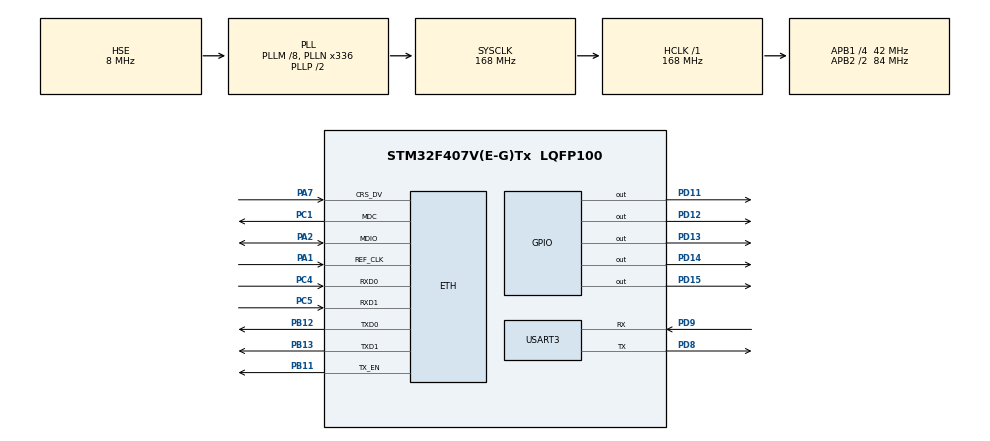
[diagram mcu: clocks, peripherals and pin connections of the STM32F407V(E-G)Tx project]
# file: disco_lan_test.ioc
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ETH.MACAddr=00\:80\:E1\:CB\:BB\:FF
ETH.MediaInterface=ETH_MEDIA_INTERFACE_RMII
LWIP.GATEWAY_ADDRESS=169.254.193.090
LWIP.IP_ADDRESS=169.254.193.140
LWIP.LWIP_DHCP=0
LWIP.LWIP_HTTPD=1
LWIP.NETMASK_ADDRESS=255.255.000.000
LWIP.Version=v2.0.3_Cube
Mcu.Family=STM32F4
Mcu.Name=STM32F407V(E-G)Tx
Mcu.Package=LQFP100
NVIC.PriorityGroup=NVIC_PRIORITYGROUP_0
PA1.Mode=RMII
PA1.Signal=ETH_REF_CLK
PA2.Mode=RMII
PA2.Signal=ETH_MDIO
PA7.Mode=RMII
PA7.Signal=ETH_CRS_DV
PB11.Mode=RMII
PB11.Signal=ETH_TX_EN
PB12.Mode=RMII
PB12.Signal=ETH_TXD0
PB13.Mode=RMII
PB13.Signal=ETH_TXD1
PC1.Mode=RMII
PC1.Signal=ETH_MDC
PC14-OSC32_IN.Mode=LSE-External-Oscillator
PC14-OSC32_IN.Signal=RCC_OSC32_IN
PC15-OSC32_OUT.Mode=LSE-External-Oscillator
PC15-OSC32_OUT.Signal=RCC_OSC32_OUT
PC4.Mode=RMII
PC4.Signal=ETH_RXD0
PC5.Mode=RMII
PC5.Signal=ETH_RXD1
PD11.Signal=GPIO_Output
PD12.Signal=GPIO_Output
PD13.Signal=GPIO_Output
PD14.Signal=GPIO_Output
PD15.Signal=GPIO_Output
PD8.Mode=Asynchronous
PD8.Signal=USART3_TX
PD9.Mode=Asynchronous
PD9.Signal=USART3_RX
PH0-OSC_IN.Mode=HSE-External-Oscillator
PH0-OSC_IN.Signal=RCC_OSC_IN
PH1-OSC_OUT.Mode=HSE-External-Oscillator
PH1-OSC_OUT.Signal=RCC_OSC_OUT
ProjectManager.HeapSize=0x200
ProjectManager.StackSize=0x400
ProjectManager.TargetToolchain=TrueSTUDIO
RCC.48MHZClocksFreq_Value=48000000
RCC.AHBFreq_Value=168000000
RCC.APB1CLKDivider=RCC_HCLK_DIV4
RCC.APB1Freq_Value=42000000
RCC.APB1TimFreq_Value=84000000
RCC.APB2CLKDivider=RCC_HCLK_DIV2
RCC.APB2Freq_Value=84000000
RCC.APB2TimFreq_Value=168000000
RCC.CortexFreq_Value=168000000
RCC.HCLKFreq_Value=168000000
RCC.HSE_VALUE=8000000
RCC.HSI_VALUE=16000000
RCC.PLLM=8
RCC.PLLN=336
RCC.PLLQ=7
RCC.PLLSourceVirtual=RCC_PLLSOURCE_HSE
RCC.SYSCLKFreq_VALUE=168000000
RCC.SYSCLKSource=RCC_SYSCLKSOURCE_PLLCLK
RCC.VCOOutputFreq_Value=336000000
USART3.VirtualMode=VM_ASYNC
VP_LWIP_VS_Enabled.Mode=Enabled
board=STM32F4DISCOVERY

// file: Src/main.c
/* USER CODE BEGIN Header */
/**
  ******************************************************************************
  * @file           : main.c
  * @brief          : Main program body
  ******************************************************************************
  * @attention
  *
  * <h2><center>&copy; Copyright (c) 2020 STMicroelectronics.
  * All rights reserved.</center></h2>
  *
  * This software component is licensed by ST under Ultimate Liberty license
  * SLA0044, the "License"; You may not use this file except in compliance with
  * the License. You may obtain a copy of the License at:
  *                             www.st.com/SLA0044
  *
  ******************************************************************************
  */
/* USER CODE END Header */

#include "main.h"
#include "lwip.h"

UART_HandleTypeDef huart3;

void SystemClock_Config(void);
static void MX_GPIO_Init(void);
static void MX_USART3_UART_Init(void);

int main(void)
{

  /* MCU Configuration--------------------------------------------------------*/

  /* Reset of all peripherals, Initializes the Flash interface and the Systick. */
  HAL_Init();

  /* Configure the system clock */
  SystemClock_Config();

  /* Initialize all configured peripherals */
  MX_GPIO_Init();
  MX_USART3_UART_Init();
  MX_LWIP_Init();

  /* Infinite loop */
  while (1)
  {

    /* USER CODE BEGIN 3 */
	  HAL_GPIO_TogglePin(GPIOD, GPIO_PIN_11|GPIO_PIN_12|GPIO_PIN_13|GPIO_PIN_14
	                          |GPIO_PIN_15);
	  MX_LWIP_Process();
  }
  /* USER CODE END 3 */
}

void SystemClock_Config(void)
{
  RCC_OscInitTypeDef RCC_OscInitStruct = {0};
  RCC_ClkInitTypeDef RCC_ClkInitStruct = {0};

  /** Configure the main internal regulator output voltage
  */
  __HAL_RCC_PWR_CLK_ENABLE();
  __HAL_PWR_VOLTAGESCALING_CONFIG(PWR_REGULATOR_VOLTAGE_SCALE1);
  /** Initializes the CPU, AHB and APB busses clocks
  */
  RCC_OscInitStruct.OscillatorType = RCC_OSCILLATORTYPE_HSE;
  RCC_OscInitStruct.HSEState = RCC_HSE_ON;
  RCC_OscInitStruct.PLL.PLLState = RCC_PLL_ON;
  RCC_OscInitStruct.PLL.PLLSource = RCC_PLLSOURCE_HSE;
  RCC_OscInitStruct.PLL.PLLM = 8;
  RCC_OscInitStruct.PLL.PLLN = 336;
  RCC_OscInitStruct.PLL.PLLP = RCC_PLLP_DIV2;
  RCC_OscInitStruct.PLL.PLLQ = 7;
  if (HAL_RCC_OscConfig(&RCC_OscInitStruct) != HAL_OK)
  {
    Error_Handler();
  }
  /** Initializes the CPU, AHB and APB busses clocks
  */
  RCC_ClkInitStruct.ClockType = RCC_CLOCKTYPE_HCLK|RCC_CLOCKTYPE_SYSCLK
                              |RCC_CLOCKTYPE_PCLK1|RCC_CLOCKTYPE_PCLK2;
  RCC_ClkInitStruct.SYSCLKSource = RCC_SYSCLKSOURCE_PLLCLK;
  RCC_ClkInitStruct.AHBCLKDivider = RCC_SYSCLK_DIV1;
  RCC_ClkInitStruct.APB1CLKDivider = RCC_HCLK_DIV4;
  RCC_ClkInitStruct.APB2CLKDivider = RCC_HCLK_DIV2;

  if (HAL_RCC_ClockConfig(&RCC_ClkInitStruct, FLASH_LATENCY_5) != HAL_OK)
  {
    Error_Handler();
  }
}

static void MX_USART3_UART_Init(void)
{

  huart3.Instance = USART3;
  huart3.Init.BaudRate = 115200;
  huart3.Init.WordLength = UART_WORDLENGTH_8B;
  huart3.Init.StopBits = UART_STOPBITS_1;
  huart3.Init.Parity = UART_PARITY_NONE;
  huart3.Init.Mode = UART_MODE_TX_RX;
  huart3.Init.HwFlowCtl = UART_HWCONTROL_NONE;
  huart3.Init.OverSampling = UART_OVERSAMPLING_16;
  if (HAL_UART_Init(&huart3) != HAL_OK)
  {
    Error_Handler();
  }

}

static void MX_GPIO_Init(void)
{
  GPIO_InitTypeDef GPIO_InitStruct = {0};

  /* GPIO Ports Clock Enable */
  __HAL_RCC_GPIOC_CLK_ENABLE();
  __HAL_RCC_GPIOH_CLK_ENABLE();
  __HAL_RCC_GPIOA_CLK_ENABLE();
  __HAL_RCC_GPIOB_CLK_ENABLE();
  __HAL_RCC_GPIOD_CLK_ENABLE();

  /*Configure GPIO pin Output Level */
  HAL_GPIO_WritePin(GPIOD, GPIO_PIN_11|GPIO_PIN_12|GPIO_PIN_13|GPIO_PIN_14
                          |GPIO_PIN_15, GPIO_PIN_RESET);

  /*Configure GPIO pins : PD11 PD12 PD13 PD14
                           PD15 */
  GPIO_InitStruct.Pin = GPIO_PIN_11|GPIO_PIN_12|GPIO_PIN_13|GPIO_PIN_14
                          |GPIO_PIN_15;
  GPIO_InitStruct.Mode = GPIO_MODE_OUTPUT_PP;
  GPIO_InitStruct.Pull = GPIO_NOPULL;
  GPIO_InitStruct.Speed = GPIO_SPEED_FREQ_LOW;
  HAL_GPIO_Init(GPIOD, &GPIO_InitStruct);

}

void Error_Handler(void)
{
}

/************************ (C) COPYRIGHT STMicroelectronics *****END OF FILE****/
